# PIC32CZ2051CA90144 device description
Architecture: CORTEX-M7; Family: PIC32C; Series: PIC32CZCA90
Registers are 32-bit, read-write, reset 0x0 unless marked. A register's access mark holds for its fields unless they carry their own. Offsets are from the block's base; [hi:lo] are bit positions; 'fields as' and 'values as' point back to an identical list.

## DMA_DESCRIPTOR — Direct Memory Access Controller
0x00 BDNXT — NEXT BUFFER DESCRIPTOR ADDRESS POINTER
  [31:0] NXT — Next Descriptor Pointer
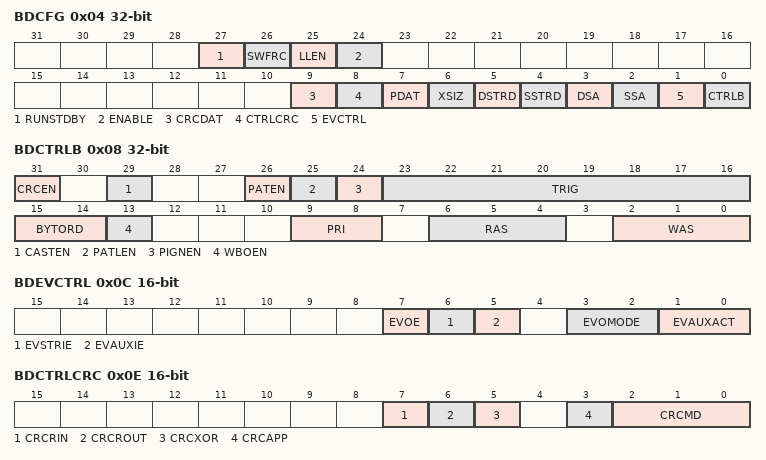
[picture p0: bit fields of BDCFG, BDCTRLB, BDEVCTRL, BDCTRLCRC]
0x04 BDCFG — CURRENT BUFFER DESCRIPTOR CONFIGURATION
  [27] RUNSTDBY — Run In Standby
  [26] SWFRC — Software Forced Trigger
  [25] LLEN — Linked List Enable
  [24] ENABLE — Channel Enable
  [9] CRCDAT — CRCDAT Register Descriptor Load
  [8] CTRLCRC — CTRLCRC Register Descriptor Load
  [7] PDAT — PDAT Register Descriptor Load
  [6] XSIZ — XSIZ Register Descriptor Load
  [5] DSTRD — DSTRD Register Descriptor Load
  [4] SSTRD — SSTRD Register Descriptor Load
  [3] DSA — DSA Register Descriptor Load
  [2] SSA — SSA Register Descriptor Load
  [1] EVCTRL — EVCTRL Register Descriptor Load
  [0] CTRLB — CTRLB Register Descriptor Load
0x08 BDCTRLB — CURRENT BUFFER DESCRIPTOR CONTROL REGISTER B
  [31] CRCEN — CRC Enable bit
  [29] CASTEN — Cell Auto Start Enable of Ensuing Transfers for this channel
  [26] PATEN — Channel Pattern Match Abort Enable.
  [25] PATLEN — Pattern Match Length
  [24] PIGNEN — Enable Pattern Ignore Byte
  [23:16] TRIG — Trigger that can Start a Channel Transfer
  [15:14] BYTORD — Byte Order
    0=BYTORD_NONE (Bytes are processed AS IS); 1=BYTORD_WORD_SWIZZLE (Bytes are swapped as: BYTE3 to BYTE0, BYTE2 to BYTE1, BYTE1 to BYTE2, and BYTE0 to BYTE3); 2=BYTORD_HALF_WORD_SWIZZLE (Bytes are swapped as: BYTE3 to BYTE1, BYTE2 to BYTE0, BYTE1 to BYTE3, and BYTE0 to BYTE2); 3=BYTORD_BYTE_SWIZZLE (Bytes are swapped as: BYTE3 to BYTE2, BYTE2 to BYTE3, BYTE1 to BYTE1, and BYTE0 to BYTE1)
  [13] WBOEN — Write Byte Order Enable
  [9:8] PRI — Channel Priority level.
    0=Channel Priority is 1; 1=Channel Priority is 2; 2=Channel Priority is 3; 3=Channel Priority is 4 (HIGHEST)
  [6:4] RAS — Channel Read Address Sequence
    0=BYTE_ADDR_INCR (Incrementing Address+1 with Transfers of Byte Operands); 1=HALF_WORD_ADDR_INCR (Incrementing Address+2 with Transfers of HalfWord Operands); 2=AUTO_ADDR_INCR (Auto Increment Address and Transfer Size); 3=FIXED_BYTE_ADDR_INCR (Fixed Byte Address (Single Byte Address with Enable Based upon 2 LSBs)); 4=FIXED_HALF_WORD_ADDR_INCR (Fixed Address of HalfWord Operand (Single HalfWord Aligned Address)); 5=FIXED_WORD_ADDR_INCR (Fixed Address Word Burst Transfer)
  [2:0] WAS — Channel Write Address Sequence.
    values as RAS
0x0C BDEVCTRL 16-bit — CURRENT BUFFER DESCRIPTOR EVENT CONTROL
  [7] EVOE — Channel Event Output Enable (0: disable; 1: enable)
  [6] EVSTRIE — Channel Start Event Input Enable (0: disable; 1:enable)
  [5] EVAUXIE — Channel Auxiliary Event Enable (0: disable; 1: enable)
  [3:2] EVOMODE — Channel Event Output Mode
    0=STRB_ON_BLCK_XFER (Generate a channel event strobe for 1 clock cycle at the end of block transfer); 1=STRB_ON_CELL_XFER (Generate a channel event strobe for 1 clock cycle at the end of cell transfer); 2=STRB_START_EVT_TRG_TO_CELL_XFER_READ (Generate a channel event strobe from start event trigger to the completion of cell transfer read); 3=STRB_START_EVT_TRG_TO_CELL_XFER_WRITE (Generate a channel event strobe from start event trigger to the completion of cell transfer write)
  [1:0] EVAUXACT — Channel Auxiliary Event Input Action
    0=ABORT_BLK_XFER (Event Aborts Bock Transfer); 1=INCR_CHN_PRI (Event Increments Channel Priority); 2=COND_TRIG (Event acts as a Conditional Trigger)
0x0E BDCTRLCRC 16-bit — CURRENT BUFFER DESCRIPTOR CRC CONTROL
  [7] CRCRIN — CRC Reflect Input Selection
  [6] CRCROUT — CRC Reflected Output Mode
  [5] CRCXOR — CRC XOR Mode
  [3] CRCAPP — CRC Append Mode
  [2:0] CRCMD — CRC/Checksum Mode
    0=CRC_16 (Normal (0x8005) CRC-16/CRC-16-IBM/CRC-16-ANSI); 1=CRC_16_CCITT (Normal (0x1021) CRC-16-CCITT); 2=16_BIT_CRCPOLYA (CRC-16 based on polynomial provided in CRCPOLYA (POLYA[15:0]) register); 3=16_BIT_CRCPOLYB (CRC-16 based on polynomial provided in CRCPOLYB (POLYB[15:0]) register); 4=CRC_32 (Normal (0x04C11DB7) CRC-32); 5=32_BIT_CRCPOLYA (CRC-32 based on polynomial provided in CRCPOLYA register); 6=32_BIT_CRCPOLYB (CRC-32 based on polynomial provided in CRCPOLYB register); 7=IP_HDR_CHECKSUM (Calculate IP header checksum)
0x10 BDSSA — CURRENT BUFFER DESCRIPTOR SOURCE START ADDRESS
  [31:0] SSA — Source Start Address
0x14 BDDSA — CURRENT BUFFER DESCRIPTOR DESTINATION START ADDRESS
  [31:0] DSA — Destination Start Address
0x18 BDSSTRD 16-bit — CURRENT BUFFER DESCRIPTOR SOURCE CELL STRIDE
  [15:0] SSTRD — Source Stride Size
0x1A BDDSTRD 16-bit — CURRENT BUFFER DESCRIPTOR DESTINATION CELL STRIDE
  [15:0] DSTRD — Destination Stride Size
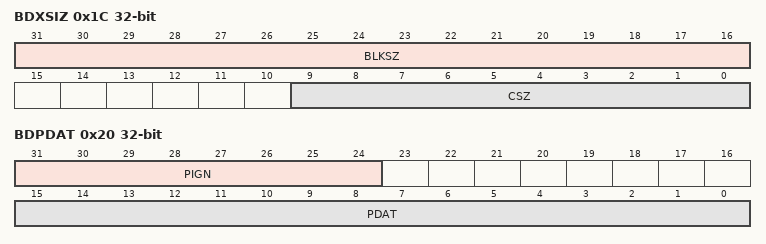
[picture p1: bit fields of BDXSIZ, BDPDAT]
0x1C BDXSIZ — CURRENT BUFFER DESCRIPTOR TRANSFER SIZE
  [31:16] BLKSZ — Block transfer size in bytes.
  [9:0] CSZ — Cell transfer size in bytes.
0x20 BDPDAT — CURRENT BUFFER DESCRIPTOR PATTERN MATCH DATA
  [31:24] PIGN — Channel Pattern Ignore Value
  [15:0] PDAT — Channel Pattern Match Data
0x24 BDCRCDAT — CURRENT BUFFER DESCRIPTOR CRC/CHECKSUM DATA
  [31:0] CRCDAT — CRC/Checksum Data Register

## Notices in the file
Copyright (c) 2021 Microchip Technology Inc.
SPDX-License-Identifier: Apache-2.0
Licensed under the Apache License, Version 2.0 (the "License");
you may not use this file except in compliance with the License.
You may obtain a copy of the License at
http://www.apache.org/licenses/LICENSE-2.0
Unless required by applicable law or agreed to in writing, software
distributed under the License is distributed on an "AS IS" BASIS,
WITHOUT WARRANTIES OR CONDITIONS OF ANY KIND, either express or implied.
See the License for the specific language governing permissions and
limitations under the License.
